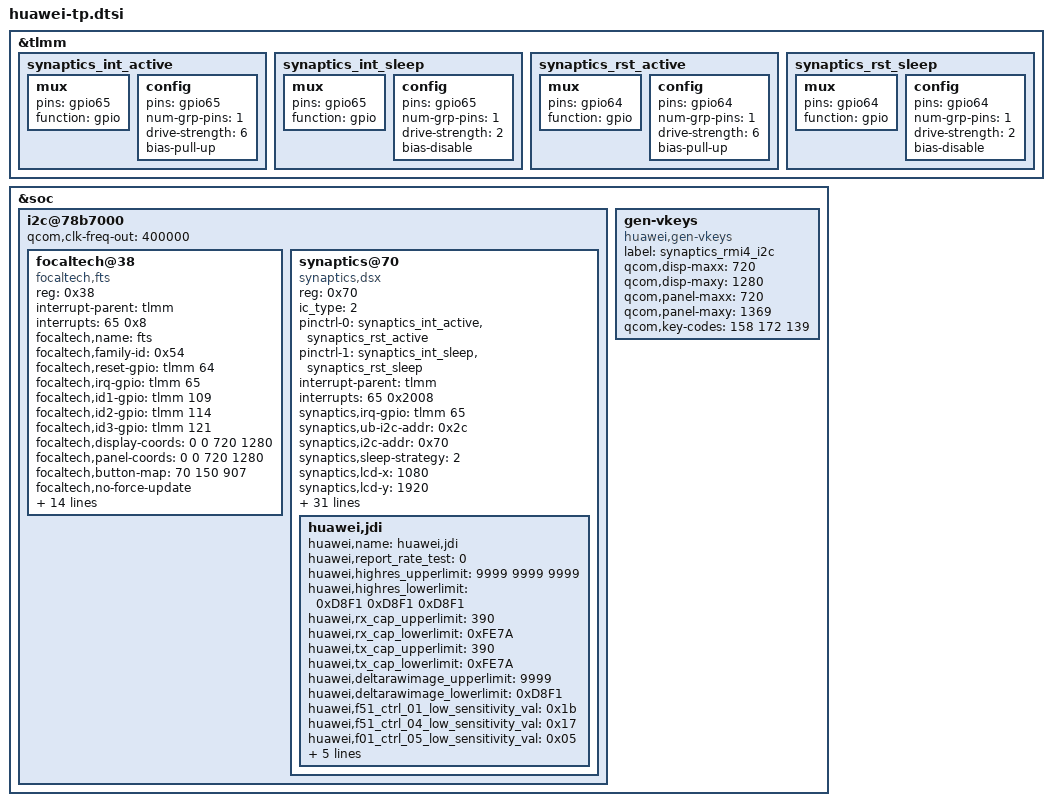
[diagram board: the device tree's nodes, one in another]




/* touch panel config */

&tlmm {
	synaptics_int_active: synaptics_int_active{
			mux {
				pins = "gpio65";
				function =  "gpio";
			};
			config {
				pins = "gpio65";
				num-grp-pins = <1>;
				drive-strength = <6>;
				bias-pull-up;
		};
	};
	synaptics_int_sleep: synaptics_int_sleep {
			mux {
				pins = "gpio65";
				function =  "gpio";
			};
			config {
				pins = "gpio65";
				num-grp-pins = <1>;
				drive-strength = <2>;
				bias-disable;
		};
	};
	synaptics_rst_active: synaptics_rst_active {
			mux {
				pins = "gpio64";
				function =  "gpio";
			};
			config {
				pins = "gpio64";
				num-grp-pins = <1>;
				drive-strength = <6>;
				bias-pull-up;
			};
		};
	synaptics_rst_sleep: synaptics_rst_sleep {
			mux {
				pins = "gpio64";
				function =  "gpio";
			};
			config {
				pins = "gpio64";
				num-grp-pins = <1>;
				drive-strength = <2>;
				bias-disable;
		};
	};
};

&soc {
	i2c@78b7000{
	status = "ok";
		#address-cells = <1>;
		#size-cells = <0>;
		qcom,clk-freq-out = <400000>;
		focaltech@38 {
			compatible = "focaltech,fts";
			reg = <0x38>;
			interrupt-parent = <&tlmm>;
			interrupts = <65 0x8>;
			//vcc_i2c-supply = <&pm8953_l6>;
			focaltech,name = "fts";
			focaltech,family-id = <0x54>;
			focaltech,reset-gpio = <&tlmm 64 0x00>;
			focaltech,irq-gpio =<&tlmm 65 0x00>;
			focaltech,id1-gpio = <&tlmm 109 0x00>;
			focaltech,id2-gpio = <&tlmm 114 0x00>;
			focaltech,id3-gpio = <&tlmm 121 0x00>;
			focaltech,display-coords = <0 0 720 1280>;
			focaltech,panel-coords = <0 0 720 1280>;
			focaltech,button-map= <70 150 907>;
			focaltech,no-force-update;
			focaltech,i2c-pull-up;
			focaltech,group-id = <1>;
			focaltech,hard-reset-delay-ms = <20>;
			focaltech,soft-reset-delay-ms = <150>;
			focaltech,num-max-touches = <10>;
			focaltech,fw-name = "FT_Upgrade_App.i";
			focaltech,fw-delay-aa-ms = <50>;
			focaltech,fw-delay-55-ms = <30>;
			focaltech,fw-upgrade-id1 = <0x79>;
			focaltech,fw-upgrade-id2 = <0x03>;
			focaltech,fw-delay-readid-ms = <10>;
			focaltech,fw-delay-era-flsh-ms = <2000>;
			focaltech,fullraw_upperlimit = <13000>;
			focaltech,fullraw_lowerlimit = <3000>;
		};
		
		synaptics@70 {
			compatible = "synaptics,dsx";
			reg = <0x70>;
			/* SYNAPTICS_S3207 = 0 */
			/* SYNAPTICS_S3350 = 1 */
			/* SYNAPTICS_S3320 = 2 */
			/* SYNAPTICS_S3718 = 3 */
			ic_type = <2>;

			pinctrl-names = "active","sleep";
			pinctrl-0 = <&synaptics_int_active &synaptics_rst_active>;
			pinctrl-1 = <&synaptics_int_sleep &synaptics_rst_sleep>;

			interrupt-parent = <&tlmm>;
			interrupts = <65 0x2008>;
			//vcc_i2c-supply = <&pm8953_l6>;
			/* Some of qcom's param will not be replaced by huawei in dtb, */
			/* just ignore them:such as "pinctrl-names","pinctrl-0","pinctrl-1", */
			/* "synaptics,display-coords","synaptics,panel-coords","synaptics,i2c-pull-up", */
			/* "synaptics,power-down","synaptics,disable-gpios"*/
			//synaptics,vdd = "vdd";
			//synaptics,vbus = "vcc_i2c";
			synaptics,irq-gpio = <&tlmm 65 0x2008>;
			//synaptics,reset-gpio = <&tlmm 64 0x0>;
			//synaptics,vci-gpio = <&tlmm 47 0x0>;
			synaptics,ub-i2c-addr=<0x2c>;
			synaptics,i2c-addr=<0x70>;

			/* synaptics,sleep/wake strategy */

			/* SLEEP_STRATEGY_DEEP_SLEEP    : 0*/
			/* SLEEP_STRATEGY_POWER_DOWN    : 1*/
			/* SLEEP_STRATEGY_KEEP_WAKE     : 2*/
			/* SLEEP_STRATEGY_ALWAYS_RESET  : 3*/
			synaptics,sleep-strategy = <2>;

			synaptics,lcd-x = <1080>;
			synaptics,lcd-y = <1920>;
			synaptics,lcd-all = <1920>;
			synaptics,virtual_keys = /* KeyCode CenterX CenterY Width Height */
				/* KEY_BACK */
				<158 142 1342 150 100
				/* KEY_HOME(172) */
				172 360 1342 150 100
				/* KEY_MENU */
				139 578 1342 150 100>;

			/* SYNAPTICS_WAKE_UP_GESTURE_FLAG:'1'->enabled,'0'->disabled */
			/*IC flash is not enough for holster,so fw del one gesture*/
			synaptics,gesture_enabled = <0>;
			/* Gestures that supported:                           */
			/* bit0  Double tap                                        */
			/* bit1  Single finger slide from left to right     */
			/* bit2  Single finger slide from right to left     */
			/* bit3  Single finger slide from top to bottom  */
			/* bit4  Single finger slide from bottom to top  */
			/* bit5  Double finger slide from top to bottom--disable for holster*/
			/* bit6  Single finger slide circle                     */
			/* bit7  Single finger write letter c                  */
			/* bit8  Single finger write letter e                  */
			/* bit9  Single finger write letter m                 */
			/* bit10 Single finger write letter w                 */
			/* bit11 Palm off screen                                */
			synaptics,easy_wakeup_supported_gestures = <0xF81>;

			/*Defination of report key value  for different gestures*/
			synaptics,easy_wakeup_gesture_keys = 
			<	59 /*0.Double tap:                                  KEY_F1*/
				60 /*1.Single finger slide from left to right:      KEY_F2*/
				61 /*2.Single finger slide from right to left:      KEY_F3*/
				62 /*3.Single finger slide from top to bottom:      KEY_F4*/
				63 /*4.Single finger slide from bottom to top:      KEY_F5*/
				64 /*5.Single finger slide circle clockwise:        KEY_F6*/
				65 /*6.Single finger slide circle counter-clockwise:KEY_F7*/
				66 /*7.Single finger write letter c:                KEY_F8*/
				67 /*8.Single finger write letter e:                KEY_F9*/
				68 /*9.Single finger write letter m:                KEY_F10*/
				87 /*10.Single finger write letter w:               KEY_F11*/
				88 /*11.Palm off screen:                            KEY_F12*/
			>;

			/* Double-tap-zone defined by huawei */
			/* Shielded area is:1cm left,1cm right,3cm up,2cm down */
			huawei,dtz_x0 = <1>;
			huawei,dtz_y0 = <1>;
			huawei,dtz_x1 = <1080>;
			huawei,dtz_y1 = <1920>;

			/* GLOVE FLAG default state:'1'->enabled,'0'->disabled*/
			synaptics,glove_enabled = <0>;
			/*After reduce power-consumption by exit reduce mode,*/
			/*we have to reduce f-r rate to make sure gesture work fine*/
			synaptics,fast_relax_gesture = <0>;
			/*Holster support flag*/
			synaptics,holster_supported = <1>;
			synaptics,roi_supported = <0>;
			synaptics,glove_edge_switch_supported = <0>;
			synaptics,grip_algorithm_supported = <0>;
			synaptics,grip_algorithm_enabled = <0>;
			huawei,grip_left_lsb = <0x32>;
			huawei,grip_left_msb = <0x0>;
			huawei,grip_right_lsb = <0x1A>;
			huawei,grip_right_msb = <0x04>;

			/*dwt represent doze wakeup threshold in gesture mode*/
			synaptics,ofilm_dwt = <30>;
			synaptics,truly_dwt = <30>;
			synaptics,junda_dwt = <30>;

			synaptics,reset-on-status = <0>;
			synaptics,power-delay-ms = <160>;
			synaptics,reset-delay-ms = <200>;
			synaptics,reset-active-ms = <10>;
			synaptics,product_name = "toronto";

			/*capacitance self-adapt*/
			huawei,jdi {
				huawei,name = "huawei,jdi";
				huawei,report_rate_test = <0>; /* 0:disable test, 1:enable test */

				huawei,highres_upperlimit = <9999 9999 9999>;
				huawei,highres_lowerlimit = <0xD8F1 0xD8F1 0xD8F1>;/* 0xD8F1 == -9999 */

				huawei,rx_cap_upperlimit = <390>;
				huawei,rx_cap_lowerlimit = <0xFE7A>;

				huawei,tx_cap_upperlimit = <390>;
				huawei,tx_cap_lowerlimit = <0xFE7A>;

				huawei,deltarawimage_upperlimit = <9999>;
				huawei,deltarawimage_lowerlimit = <0xD8F1>;

				huawei,f51_ctrl_01_low_sensitivity_val = <0x1b>;
				huawei,f51_ctrl_04_low_sensitivity_val = <0x17>;
				huawei,f01_ctrl_05_low_sensitivity_val = <0x05>;
				huawei,f01_ctrl_09_low_sensitivity_val = <0x04>;

				huawei,fullraw_upperlimit =
					<2550 2550 2550 2550 2550 2550 2550 2550 2550 2550 2550 2550 2550 2550 2550 2550
					2550 2550 2550 2550 2550 2550 2550 2550 2550 2550 2550 2550 2550 2550 2550 2550
					2550 2550 2550 2550 2550 2550 2550 2550 2550 2550 2550 2550 2550 2550 2550 2550
					2550 2550 2550 2550 2550 2550 2550 2550 2550 2550 2550 2550 2550 2550 2550 2550
					2550 2550 2550 2550 2550 2550 2550 2550 2550 2550 2550 2550 2550 2550 2550 2550
					2550 2550 2550 2550 2550 2550 2550 2550 2550 2550 2550 2550 2550 2550 2550 2550
					2550 2550 2550 2550 2550 2550 2550 2550 2550 2550 2550 2550 2550 2550 2550 2550
					2550 2550 2550 2550 2550 2550 2550 2550 2550 2550 2550 2550 2550 2550 2550 2550
					2550 2550 2550 2550 2550 2550 2550 2550 2550 2550 2550 2550 2550 2550 2550 2550
					2550 2550 2550 2550 2550 2550 2550 2550 2550 2550 2550 2550 2550 2550 2550 2550
					2550 2550 2550 2550 2550 2550 2550 2550 2550 2550 2550 2550 2550 2550 2550 2550
					2550 2550 2550 2550 2550 2550 2550 2550 2550 2550 2550 2550 2550 2550 2550 2550
					2550 2550 2550 2550 2550 2550 2550 2550 2550 2550 2550 2550 2550 2550 2550 2550
					2550 2550 2550 2550 2550 2550 2550 2550 2550 2550 2550 2550 2550 2550 2550 2550
					2550 2550 2550 2550 2550 2550 2550 2550 2550 2550 2550 2550 2550 2550 2550 2550
					2550 2550 2550 2550 2550 2550 2550 2550 2550 2550 2550 2550 2550 2550 2550 2550
					2550 2550 2550 2550 2550 2550 2550 2550 2550 2550 2550 2550 2550 2550 2550 2550
					2550 2550 2550 2550 2550 2550 2550 2550 2550 2550 2550 2550 2550 2550 2550 2550
					2550 2550 2550 2550 2550 2550 2550 2550 2550 2550 2550 2550 2550 2550 2550 2550
					2550 2550 2550 2550 2550 2550 2550 2550 2550 2550 2550 2550 2550 2550 2550 2550
					2550 2550 2550 2550 2550 2550 2550 2550 2550 2550 2550 2550 2550 2550 2550 2550
					2550 2550 2550 2550 2550 2550 2550 2550 2550 2550 2550 2550 2550 2550 2550 2550
					2550 2550 2550 2550 2550 2550 2550 2550 2550 2550 2550 2550 2550 2550 2550 2550
					2550 2550 2550 2550 2550 2550 2550 2550 2550 2550 2550 2550 2550 2550 2550 2550
					2550 2550 2550 2550 2550 2550 2550 2550 2550 2550 2550 2550 2550 2550 2550 2550
					2550 2550 2550 2550 2550 2550 2550 2550 2550 2550 2550 2550 2550 2550 2550 2550
					2550 2550 2550 2550 2550 2550 2550 2550 2550 2550 2550 2550 2550 2550 2550 2550
					2550 2550 2550 2550 2550 2550 2550 2550 2550 2550 2550 2550 2550 2550 2550 2550>;

				huawei,fullraw_lowerlimit =
					<1500 1500 1500 1500 1500 1500 1500 1500 1500 1500 1500 1500 1500 1500 1500 1500
					1500 1500 1500 1500 1500 1500 1500 1500 1500 1500 1500 1500 1500 1500 1500 1500
					1500 1500 1500 1500 1500 1500 1500 1500 1500 1500 1500 1500 1500 1500 1500 1500
					1500 1500 1500 1500 1500 1500 1500 1500 1500 1500 1500 1500 1500 1500 1500 1500
					1500 1500 1500 1500 1500 1500 1500 1500 1500 1500 1500 1500 1500 1500 1500 1500
					1500 1500 1500 1500 1500 1500 1500 1500 1500 1500 1500 1500 1500 1500 1500 1500
					1500 1500 1500 1500 1500 1500 1500 1500 1500 1500 1500 1500 1500 1500 1500 1500
					1500 1500 1500 1500 1500 1500 1500 1500 1500 1500 1500 1500 1500 1500 1500 1500
					1500 1500 1500 1500 1500 1500 1500 1500 1500 1500 1500 1500 1500 1500 1500 1500
					1500 1500 1500 1500 1500 1500 1500 1500 1500 1500 1500 1500 1500 1500 1500 1500
					1500 1500 1500 1500 1500 1500 1500 1500 1500 1500 1500 1500 1500 1500 1500 1500
					1500 1500 1500 1500 1500 1500 1500 1500 1500 1500 1500 1500 1500 1500 1500 1500
					1500 1500 1500 1500 1500 1500 1500 1500 1500 1500 1500 1500 1500 1500 1500 1500
					1500 1500 1500 1500 1500 1500 1500 1500 1500 1500 1500 1500 1500 1500 1500 1500
					1500 1500 1500 1500 1500 1500 1500 1500 1500 1500 1500 1500 1500 1500 1500 1500
					1500 1500 1500 1500 1500 1500 1500 1500 1500 1500 1500 1500 1500 1500 1500 1500
					1500 1500 1500 1500 1500 1500 1500 1500 1500 1500 1500 1500 1500 1500 1500 1500
					1500 1500 1500 1500 1500 1500 1500 1500 1500 1500 1500 1500 1500 1500 1500 1500
					1500 1500 1500 1500 1500 1500 1500 1500 1500 1500 1500 1500 1500 1500 1500 1500
					1500 1500 1500 1500 1500 1500 1500 1500 1500 1500 1500 1500 1500 1500 1500 1500
					1500 1500 1500 1500 1500 1500 1500 1500 1500 1500 1500 1500 1500 1500 1500 1500
					1500 1500 1500 1500 1500 1500 1500 1500 1500 1500 1500 1500 1500 1500 1500 1500
					1500 1500 1500 1500 1500 1500 1500 1500 1500 1500 1500 1500 1500 1500 1500 1500
					1500 1500 1500 1500 1500 1500 1500 1500 1500 1500 1500 1500 1500 1500 1500 1500
					1500 1500 1500 1500 1500 1500 1500 1500 1500 1500 1500 1500 1500 1500 1500 1500
					1500 1500 1500 1500 1500 1500 1500 1500 1500 1500 1500 1500 1500 1500 1500 1500
					1500 1500 1500 1500 1500 1500 1500 1500 1500 1500 1500 1500 1500 1500 1500 1500
					1500 1500 1500 1500 1500 1500 1500 1500 1500 1500 1500 1500 1500 1500 1500 1500>;
			};
		};
	};

	/*To disable gen-vkeys.c probe,avoid generate kobject*/
	gen-vkeys {
		compatible = "huawei,gen-vkeys";
		label = "synaptics_rmi4_i2c";
		qcom,disp-maxx = <720>;
		qcom,disp-maxy = <1280>;
		qcom,panel-maxx = <720>;
		qcom,panel-maxy = <1369>;
		qcom,key-codes = <158 172 139>;
	};
};

